# nrf54h20_enga_secure register map
Vendor: Nordic Semiconductor; Series: nRF54h; File version: 1
CPU: CM33 r0p4, little endian, MPU, no FPU, 3 interrupt priority bits, 480 interrupts, 4 SAU regions
Registers are 32-bit, read-write, reset 0x0 unless marked. A register's access mark holds for its fields unless they carry their own. Offsets are from the block's base; [hi:lo] are bit positions; lines under a group give offsets from that group; {n}, {i} and the like mark numbered series; 'fields as' and 'values as' point back to an identical list.

## CPUCONF_NS — CPU Configuration 0
Base 0x41011000
Same registers: CPUCONF_S 0x51011000
0x00 TASKS_ERASECACHE wo — Erase the caches used by the CPU.
  [0] TASKS_ERASECACHE
    1=Trigger task
0x500 INITSVTOR reset 0x1000000 — Initial value of the secure VTOR (Vector Table Offset Register) after CPU reset.
  [31:0] INITSVTOR — Initial value of the VTOR.
0x504 INITNSVTOR reset 0x1000000 — Initial value of the non-secure VTOR (Vector Table Offset Register).
  [31:0] INITNSVTOR — Initial value of the VTOR.
0x508 CPUSTART reset 0x1 — Enable for starting the CPU
  [0] EN — Enable to start the CPU.
    0=Stopped (CPU stopped.); 1=Started (CPU started.)
0x50C CPUWAIT — Enable for the CPU wait.
  [0] EN — Enable to the CPU wait.
    0=Disabled (CPU is not waiting.); 1=Enabled (CPU is waiting.)

## MUTEX_NS — MUTEX 0
Base 0x41017000
Same registers: MUTEX_S 0x51017000
{0x400+4i} MUTEX[{i}] (i=0..7) — Description collection: Mutex register
  [0] MUTEX — Mutex register n
    0=Unlocked (Mutex n is in unlocked state); 1=Locked (Mutex n is in locked state)

## BILS_S — The Built-in Leakage Sensor (BILS) module.
Base 0x51019000
0x400 CONFIG group — Unspecified
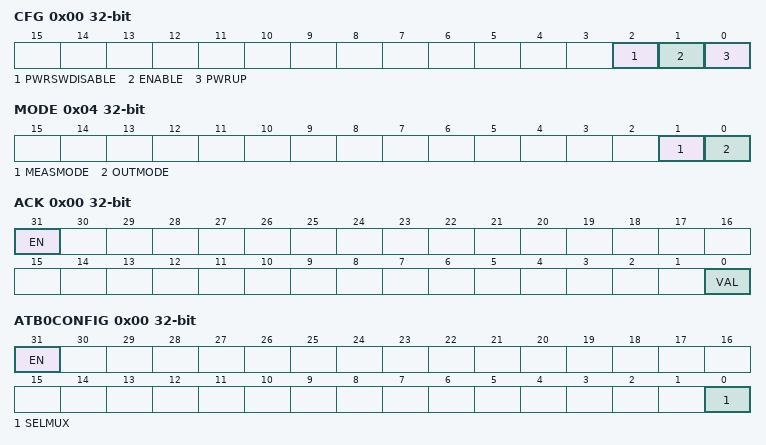
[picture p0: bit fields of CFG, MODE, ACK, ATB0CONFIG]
  0x00 CFG — BILS configuration
    [2] PWRSWDISABLE — Disable power switch.
      0=PwrSwNormalMode (Normal control of the power switch.); 1=PwrSwDisabledMode (Power switch is turned off.)
    [1] ENABLE — BILS enable
      0=BilsDisable (Disable BILS, REQ_SWOFF_AO_0V8 = 0); 1=BilsEnable (Enable BILS, REQ_SWOFF_AO_0V8 is controlled by BILS)
    [0] PWRUP — Power up BILS
      0=PwrOff (BILS is powered down and REQ_SWOFF_AO_0V8=0); 1=PwrOn (BILS is powered up)
  0x04 MODE — Mode selection
    [1] MEASMODE — Measurement mode selection
      0=MeasDisMode (Measure discharge rate); 1=MeasPwMode (Measure power switch chain propagation delay)
    [0] OUTMODE — Output mode selection
      0=Duty50Mode (50:50 duty cycle output selected to FOUT_AO_0V8 pin); 1=CompMode (Comparator output selected to FOUT_AO_0V8 pin)
0x500 OVERRIDE group — Unspecified
  0x00 ACK — Override the ACL_SWOFF_0V8 signal
    [31] EN — Override enable
      0=Disabled (Override disabled); 1=Enabled (Override is enabled)
    [0] VAL — Override value
0x600 DFT group — Unspecified
  0x00 ATB0CONFIG — Analog Test Bus 0 (ATB0) configuration
    [31] EN — Enable the analog test bus
      0=Disabled (Analog test bus is disabled); 1=Enabled (Analog test bus is enabled)
    [0] SELMUX — Select multiplexer for ATB0
      0=None selected; 1=Connect (Voltage on ATB0 used as threshold voltage)
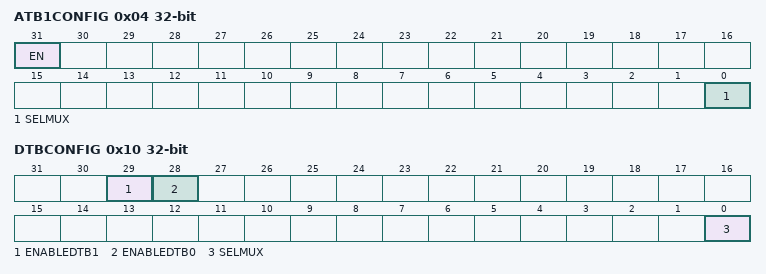
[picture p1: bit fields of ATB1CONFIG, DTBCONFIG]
  0x04 ATB1CONFIG — Analog Test Bus 1 (ATB1) configuration
    [31] EN — Enable the analog test bus
      values as DFT.ATB0CONFIG.EN
    [0] SELMUX — Select multiplexer for ATB1
      0=None selected; 1=ConnectDVDD (ATB1 connected to DVDD_0V8_SW)
  0x10 DTBCONFIG — Digital Test Bus configuration
    [29] ENABLEDTB1 — Enable the digital test bus
      0=Disabled (Digital test bus is disabled); 1=Enabled (Digital test bus is enabled)
    [28] ENABLEDTB0 — Enable the digital test bus
      values as ENABLEDTB1
    [0] SELMUX — Select multiplexer for DTB0
      0=None selected; 1=Connect (FOUT_AO_0V8 is connected to DTB0, REQ_SWOFF_AO_0V8 is connected to DTB1)

## RESETINFO_S — RESETINFO
Base 0x5101E000; alternate view of LRCCONF010_S
0x4A0 RESETREAS group — Unspecified
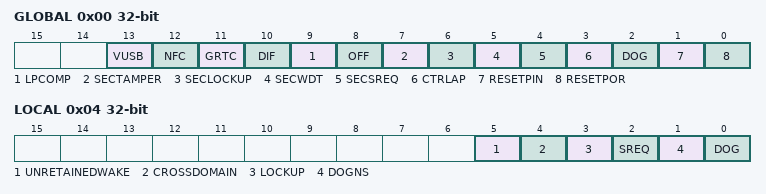
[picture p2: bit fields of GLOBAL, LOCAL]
  0x00 GLOBAL — Global reset reason.
    [all] fields
      0=NotDetected; 1=Detected
    [13] VUSB — Reset after wakeup from System OFF mode due to VBUS rising into valid range.
    [12] NFC — Reset due to wakeup from System OFF mode when wakeup is triggered by NFC field detection in sense mode.
    [11] GRTC — Reset due to wakeup from System OFF mode when wakeup is triggered by GRTC interrupt.
    [10] DIF — Reset due to wakeup from System OFF mode when wakeup is triggered by entering the debug interface mode.
    [9] LPCOMP — Reset due to wakeup from System OFF mode when wakeup is triggered by LPCOMP (Low Power Comparator).
    [8] OFF — Reset due to wakeup from System OFF mode when wakeup is triggered by DETECT signal from GPIO.
    [7] SECTAMPER — Reset due to secure domain tamper detected
    [6] SECLOCKUP — Reset due to secure domain lockup.
    [5] SECWDT — Reset due to secure domain watchdog timer detected.
    [4] SECSREQ — Reset due to secure domain system reset request.
    [3] CTRLAP — Reset from CTRL-AP detected.
    [2] DOG — Reset from the SysCtrl watchdog timer detected.
    [1] RESETPIN — Reset from pin reset detected.
    [0] RESETPOR — Reset from power on reset.
  0x04 LOCAL — Local reset reason.
    [5] UNRETAINEDWAKE — Reset due to wake from unretained state.
    [4] CROSSDOMAIN — Reset due to cross domain reset source.
      0=NotDetected; 1=Detected
    [3] LOCKUP — Reset from local CPU lockup detected
      0=NotDetected; 1=Detected
    [2] SREQ — Reset from the local soft reset request detected.
      0=NotDetected; 1=Detected
    [1] DOGNS — Reset from the local non-secure watchdog timer detected
      0=NotDetected; 1=Detected
    [0] DOG — Reset from the local watchdog timer detected
      0=NotDetected; 1=Detected
  0x08 ERROR group — Unspecified
    0x00 STATUS — Reset error status.
      [3:0] ERRORSTATUS
    0x04 ADDRESS — Reset error address.
      [31:0] ERRORADDRESS
0x4C0 RESTOREVALID write-1-clears — Valid restore image is present in RAM.
  [0] RESTOREVALID
    0=NotPreset (Not present); 1=Present
0x4C4 MASKLOCKUP — Mask CPU lockup signal.
  [0] MASK — Mask lockup signal
    0=NotMask (Do not mask lockup signal); 1=Mask lockup signal
